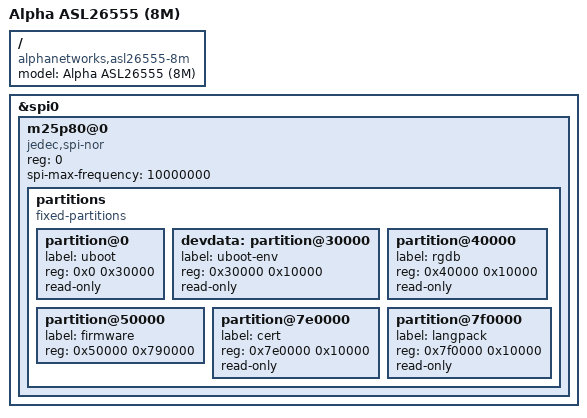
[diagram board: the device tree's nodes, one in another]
/dts-v1/;

#include "ASL26555.dtsi"

/ {
	compatible = "alphanetworks,asl26555-8m", "alphanetworks,asl26555", "ralink,rt3050-soc";
	model = "Alpha ASL26555 (8M)";
};

&spi0 {
	status = "okay";

	m25p80@0 {
		compatible = "jedec,spi-nor";
		reg = <0>;
		spi-max-frequency = <10000000>;

		partitions {
			compatible = "fixed-partitions";
			#address-cells = <1>;
			#size-cells = <1>;

			partition@0 {
				label = "uboot";
				reg = <0x0 0x30000>;
				read-only;
			};

			devdata: partition@30000 {
				label = "uboot-env";
				reg = <0x30000 0x10000>;
				read-only;
			};

			partition@40000 {
				label = "rgdb";
				reg = <0x40000 0x10000>;
				read-only;
			};

			partition@50000 {
				label = "firmware";
				reg = <0x50000 0x790000>;
			};

			partition@7e0000 {
				label = "cert";
				reg = <0x7e0000 0x10000>;
				read-only;
			};

			partition@7f0000 {
				label = "langpack";
				reg = <0x7f0000 0x10000>;
				read-only;
			};
		};
	};
};
